# MKM38Z5 register map
File version: 1.6
Registers are 8-bit, read-write, reset 0x0 unless marked. A register's access mark holds for its fields unless they carry their own. Offsets are from the block's base; [hi:lo] are bit positions; {n}, {i} and the like mark numbered series.

## SIM — System Integration Module
Base 0x4003E000; register names take the prefix SIM_
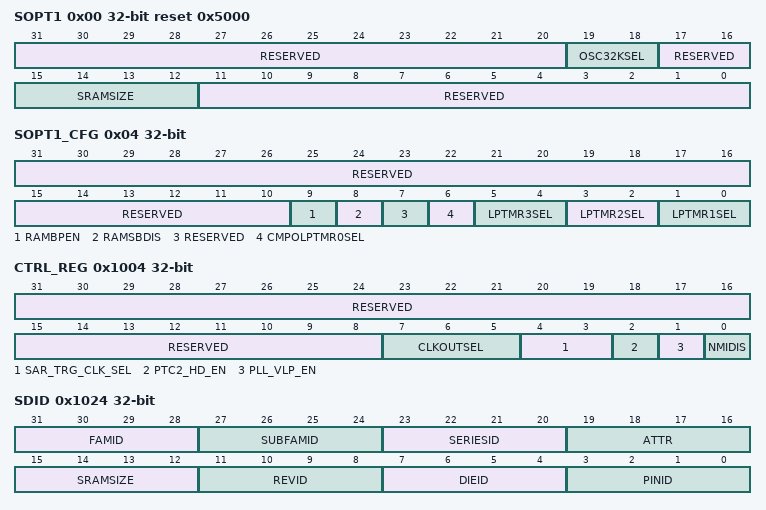
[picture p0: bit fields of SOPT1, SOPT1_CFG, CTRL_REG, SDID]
0x00 SOPT1 32-bit reset 0x5000 — System Options Register 1
  [31:20] RESERVED ro
  [19:18] OSC32KSEL — 32K oscillator clock select
    0=OSC32KCLK; 1=ERCLK32K; 2=MCGIRCLK; 3=LPO
  [17:16] RESERVED ro
  [15:12] SRAMSIZE ro — Returns the size of the system RAM
    5=16kB System RAM
  [11:0] RESERVED ro
0x04 SOPT1_CFG 32-bit — SOPT1 Configuration Register
  [31:10] RESERVED ro
  [9] RAMBPEN — RAM Bitline Precharge Enable
    0=Bitline precharge of system SRAM disabled during VLPR and VLPW modes; 1=Bitline precharge of system SRAM enabled during VLPR and VLPW modes
  [8] RAMSBDIS
    0=Source bias of System SRAM enabled during VLPR and VLPW modes; 1=Source bias of System SRAM disabled during VLPR and VLPW modes
  [7] RESERVED ro
  [6] CMPOLPTMR0SEL — Comparator output selection for LPTMR channel0
    0=CMP[1] output selected as LPTMR input[0]; 1=CMP[0] output selected as LPTMR input[0]
  [5:4] LPTMR3SEL — LP timer Channel3 Select
    0=Pad PTD5; 1=Pad PTG0; 2=Pad PTG6
  [3:2] LPTMR2SEL — LP timer Channel2 Select
    0=Pad PTD6; 1=Pad PTF3; 2=Pad PTG5
  [1:0] LPTMR1SEL — LP timer Channel1 Select
    0=Pad PTE4; 1=Pad PTF4; 2=Pad PTG1
0x1004 CTRL_REG 32-bit — System Control Register
  [31:8] RESERVED ro
  [7:5] CLKOUTSEL — Clock out Select
    0=Disabled; 1=Gated Core Clk; 2=Bus/Flash Clk; 3=LPO clock from PMC; 4=IRC clock from MCG; 5=Muxed 32Khz source (please refer SOPT1[19:18] for possible options); 6=MHz Oscillator external reference clock; 7=PLL clock output from MCG
  [4:3] SAR_TRG_CLK_SEL — SAR ADC Trigger Clk Select
    0=Bus Clock (During Low Power Modes such as stop, the Bus clock is not available for conversion and should not be selected in case a conversion needs to be performed while in stop); 1=ADC asynchronous Clock; 2=ERCLK32K; 3=OSCCLK
  [2] PTC2_HD_EN — PTC2 HighDrive Enable
  [1] PLL_VLP_EN — PLL VLP Enable
  [0] NMIDIS — NMI Disable
    0=NMI enabled; 1=NMI disabled
0x1024 SDID 32-bit ro reset not defined — System Device Identification Register
  [31:28] FAMID — Metering family ID
    1=Device derivatives without LCD; 3=Device derivatives with LCD
  [27:24] SUBFAMID — Sub-Family ID
    2=Device derivatives with 2 AFE enabled (AFE Channels 0 and 2 are enabled); 3=Device derivatives with 3 AFE enabled (AFE Channels 0, 1, and 2 are enabled); 4=Device derivatives with 4 AFE enabled
  [23:20] SERIESID
    3=Metering Series
  [19:16] ATTR — Attribute ID
    0=M0+ core
  [15:12] SRAMSIZE
    5=16kB SRAM
  [11:8] REVID — Revision ID
    1=Second Cut
  [7:4] DIEID
    0=First cut
  [3:0] PINID — Pincount identification
    3=44-pin; 5=64-pin; 8=100-pin
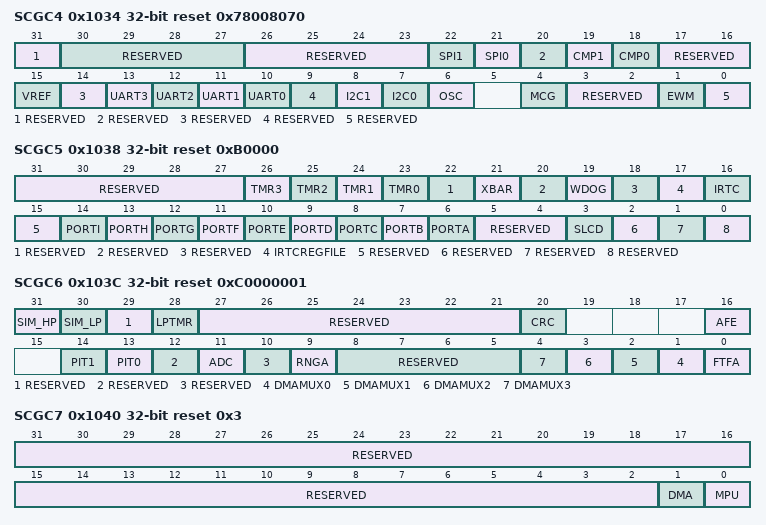
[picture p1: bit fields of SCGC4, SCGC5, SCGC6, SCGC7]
0x1034 SCGC4 32-bit reset 0x78008070 — System Clock Gating Control Register 4
  [31] RESERVED ro
  [30:27] RESERVED ro
  [26:23] RESERVED ro
  [22] SPI1 — SPI1 Clock Gate Control
    0=Clock disabled; 1=Clock enabled
  [21] SPI0 — SPI0 Clock Gate Control
    0=Clock disabled; 1=Clock enabled
  [20] RESERVED ro
  [19] CMP1 — High Speed Comparator1 Clock Gate Control.
    0=Clock disabled; 1=Clock enabled
  [18] CMP0 — High Speed Comparator0 Clock Gate Control.
    0=Clock disabled; 1=Clock enabled
  [17:16] RESERVED ro
  [15] VREF — VREF Clock Gate Control
    0=Clock disabled; 1=Clock enabled
  [14] RESERVED ro
  [n+10] UART{n} (n=0..3) — UART{n} Clock Gate Control
    0=Clock disabled; 1=Clock enabled
  [9] RESERVED ro
  [8] I2C1 — I2C1 Clock Gate Control
    0=Clock disabled; 1=Clock enabled
  [7] I2C0 — I2C0 Clock Gate Control
    0=Clock disabled; 1=Clock enabled
  [6] OSC — Oscillator (Mhz) Clock Gate Control
    0=Clock disabled; 1=Clock enabled
  [4] MCG — MCG clock gate control.
    0=Clock disabled; 1=Clock enabled
  [3:2] RESERVED ro
  [1] EWM — External Watchdog Monitor Clock gate control
    0=Clock disabled; 1=Clock enabled
  [0] RESERVED ro
0x1038 SCGC5 32-bit reset 0xB0000 — System Clock Gating Control Register 5
  [31:27] RESERVED ro
  [n+23] TMR{n} (n=0..3) — Quadtimer{n} Clock Gate Control
    0=Clock disabled; 1=Clock enabled
  [22] RESERVED ro
  [21] XBAR — Peripheral Crossbar Clock Gate Control
    0=Clock disabled; 1=Clock enabled
  [20] RESERVED ro
  [19] WDOG — Watchdog Clock Gate Control
    0=Clock disabled; 1=Clock enabled
  [18] RESERVED ro
  [17] IRTCREGFILE — IRTC_REG_FILE Clock Gate Control
    0=Clock disabled; 1=Clock enabled
  [16] IRTC — IRTC Clock Gate Control
    0=Clock disabled; 1=Clock enabled
  [15] RESERVED ro
  [14] PORTI — PCTLI Clock Gate Control
    0=Clock disabled; 1=Clock enabled
  [13] PORTH — PCTLH Clock Gate Control
    0=Clock disabled; 1=Clock enabled
  [12] PORTG — PCTLG Clock Gate Control
    0=Clock disabled; 1=Clock enabled
  [11] PORTF — PCTLF Clock Gate Control
    0=Clock disabled; 1=Clock enabled
  [10] PORTE — PCTLE Clock Gate Control
    0=Clock disabled; 1=Clock enabled
  [9] PORTD — PCTLD Clock Gate Control
    0=Clock disabled; 1=Clock enabled
  [8] PORTC — PCTLC Clock Gate Control
    0=Clock disabled; 1=Clock enabled
  [7] PORTB — PCTLB Clock Gate Control
    0=Clock disabled; 1=Clock enabled
  [6] PORTA — PCTLA Clock Gate Control
    0=Clock disabled; 1=Clock enabled
  [5:4] RESERVED ro
  [3] SLCD — Segmented LCD Clock Gate Control
    0=Clock disabled; 1=Clock enabled
  [2] RESERVED ro
  [1] RESERVED ro
  [0] RESERVED ro
0x103C SCGC6 32-bit reset 0xC0000001 — System Clock Gating Control Register 6
  [31] SIM_HP ro — SIM_HP Clock Gate Control
    1=Clock is always enabled to SIM
  [30] SIM_LP — SIM_LP Clock Gate Control
    1=Clock is enabled; 0=Clock is disabled
  [29] RESERVED ro
  [28] LPTMR — LPTMR Clock Gate Control
    0=Clock disabled; 1=Clock enabled
  [27:21] RESERVED ro
  [20] CRC — Programmable CRC Clock Gate Control
    0=Clock disabled; 1=Clock enabled
  [16] AFE — AFE Clock Gate Control
    0=Clock disabled; 1=Clock enabled
  [14] PIT1 — PIT1 Clock Gate Control
    0=Clock disabled; 1=Clock enabled
  [13] PIT0 — PIT0 Clock Gate Control
    0=Clock disabled; 1=Clock enabled
  [12] RESERVED ro
  [11] ADC — SAR ADC Clock Gate Control
    0=Clock disabled; 1=Clock enabled
  [10] RESERVED ro
  [9] RNGA — RNGA Clock Gate Control
    0=Clock disabled; 1=Clock enabled
  [8:5] RESERVED ro
  [n+1] DMAMUX{n} (n=0..3) — DMA MUX{n} Clock Gate Control
    0=Clock disabled; 1=Clock enabled
  [0] FTFA — FTFA Clock Gate Control
    0=Clock disabled; 1=Clock enabled
0x1040 SCGC7 32-bit reset 0x3 — System Clock Gating Control Register 7
  [31:2] RESERVED ro
  [1] DMA — DMA Clock Gate control.
    0=Clock disabled; 1=Clock enabled
  [0] MPU — MPU Clock Gate control.
    0=Clock disabled; 1=Clock enabled
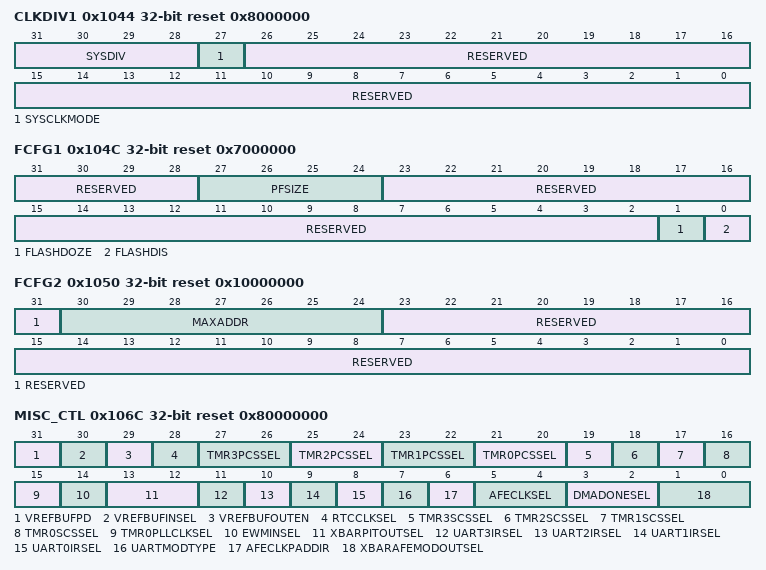
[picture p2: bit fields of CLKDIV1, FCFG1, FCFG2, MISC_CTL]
0x1044 CLKDIV1 32-bit reset 0x8000000 — System Clock Divider Register 1
  [31:28] SYSDIV — System Clock divider
    0=Divide by 1; 1=Divide by 2; 2=Divide by 3; 3=Divide by 4 and so on..... If FOPT[0] is 0, the divider is set to div-by-8 after system reset is deasserted (after completion of system initialization sequence)
  [27] SYSCLKMODE — System Clock Mode
    0=1:1:1; 1=2:1:1
  [26:0] RESERVED ro
0x104C FCFG1 32-bit reset 0x7000000 — Flash Configuration Register 1
  [31:28] RESERVED ro
  [27:24] PFSIZE ro — Program flash size
    7=64 KB of program flash memory, 2 KB protection region; 9=128 KB of program flash memory, 4 KB protection region; 15=(Default)
  [23:2] RESERVED ro
  [1] FLASHDOZE
    0=Flash remains enabled during Wait mode; 1=Flash is disabled for the duration of Wait mode
  [0] FLASHDIS — Flash Disable
    0=Flash is enabled; 1=Flash is disabled
0x1050 FCFG2 32-bit ro reset 0x10000000 — Flash Configuration Register 2
  [31] RESERVED
  [30:24] MAXADDR — Max address block
  [23:0] RESERVED
{0x1054+4i} UID{i} 32-bit ro reset not defined (i=0..3) — Unique Identification Register {i}
  [31:0] UID — Unique Identification
0x106C MISC_CTL 32-bit reset 0x80000000 — Miscellaneous Control Register
  [31] VREFBUFPD — VrefBuffer Power Down
    0=Buffer Enabled; 1=Buffer Powered Down
  [30] VREFBUFINSEL — VrefBuffer Input Select
    0=Internal Reference selected as Buffer Input; 1=External Reference selected as Buffer Input
  [29] VREFBUFOUTEN — VrefBuffer Output Enable
    0=Buffer does not drive PAD; 1=Buffer drives selected voltage (selected by vref_buffer_sel) on pad
  [28] RTCCLKSEL — RTC Clock select
    0=RTC OSC_32K clock selected; 1=32K IRC Clock selected
  [2n+21:2n+20] TMR{n}PCSSEL (n=0..3) — Quadtimer Channel{n} Primary Count Source Select
    0=Bus Clock; 1=Peripheral Crossbar Output [9]; 2=Peripheral Crossbar Output [10]; 3=Disabled
  [19] TMR3SCSSEL — Quadtimer Channel3 Secondary Count Source Select
    0=Pad PTE5 or PTD1, depending upon PCTL configuration; 1=Peripheral Crossbar (XBAR) Output[8]
  [18] TMR2SCSSEL — Quadtimer Channel2 Secondary Count Source Select
    0=Pad PTF7 or PTF0, depending upon PCTL configuration; 1=Peripheral Crossbar (XBAR) Output[7]
  [17] TMR1SCSSEL — Quadtimer Channel1 Secondary Count Source Select
    0=Pad PTG0 or PTC6, depending upon PCTL configuration; 1=Peripheral Crossbar (XBAR) Output[6]
  [16] TMR0SCSSEL — Quadtimer Channel0 Secondary Count Source Select
    0=Pad PTF1 or PTD5, depending upon PCTL configuration; 1=Peripheral Crossbar (XBAR) Output[5]
  [15] TMR0PLLCLKSEL — Timer CH0 PLL clock select
    0=Selects Bus Clock as source for the Timer CH0; 1=Selects the PLL_AFE clock as the source for Timer CH0. The PLL_AFE clock source is itself selected using the MISC_CTL[5:4]
  [14] EWMINSEL — External Watchdog Monitor Input Select
    0=Input from PAD (PTE[2] or PTE[4] as selected from Pinmux control ); 1=Peripheral Crossbar (XBAR) Output[32]
  [13:12] XBARPITOUTSEL — XBAR PIT Output select
    0=PIT0[0] (default); 1=PIT0[1]; 2=PIT1[0]; 3=PIT1[1]
  [11] UART3IRSEL — UART3 IRDA Select
    0=Pad RX input (PTC[3] or PTD[7], as selected in Pinmux control) selected for RX input of UART3 and UART3 TX signal is not used for modulation; 1=UART3 selected for IRDA modulation. UART3 TX modulated by XBAR_OUT[14] and UART3 RX input connected to XBAR_OUT[13].
  [10] UART2IRSEL — UART2 IRDA Select
    0=Pad RX input PTE[6] selected for RX input of UART2 and UART2 TX signal is not used for modulation; 1=UART2 selected for IRDA modulation. UART2 TX modulated by XBAR_OUT[14] and UART2 RX input connected to XBAR_OUT[13].
  [9] UART1IRSEL — UART1 IRDA Select
    0=Pad RX input (PTD[2] or PTI[0], as selected in Pinmux control) selected for RX input of UART1 and UART1 TX signal is not used for modulation; 1=UART1 selected for IRDA modulation. UART1 TX modulated by XBAR_OUT[14] and UART1 RX input connected to XBAR_OUT[13]
  [8] UART0IRSEL — UART0 IRDA Select
    0=Pad RX input (PTD[0] or PTF[3], as selected in Pinmux control) selected for RX input of UART0 and UART0 TX signal is not used for modulation; 1=UART0 selected for IRDA modulation. UART0 TX modulated by XBAR_OUT[14] and UART0 RX input connected to XBAR_OUT[13]
  [7] UARTMODTYPE — UART Modulation Type
    0=TypeA (ORed) Modulation selected for IRDA; 1=TypeB (ANDed) Modulation selected for IRDA
  [6] AFECLKPADDIR — AFE Clock Pad Direction
    0=AFE CLK PAD is input; 1=AFE CLK PAD is output
  [5:4] AFECLKSEL — AFE Clock Source Select
    0=MCG PLL Clock selected; 1=MCG FLL Clock selected; 2=OSC Clock selected; 3=Disabled
  [3:2] DMADONESEL — DMA Done select
    {v}=DMA{v} (v=0..3)
  [1:0] XBARAFEMODOUTSEL — XBAR AFE Modulator Output Select
    {v}=Sigma Delta Modulator {v} data output (v=0..3)
